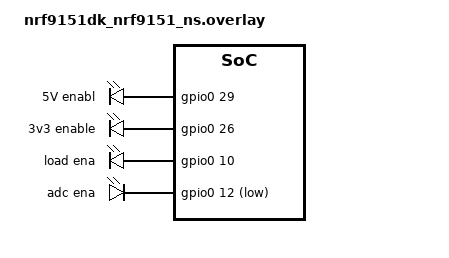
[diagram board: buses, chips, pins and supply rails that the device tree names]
// To get started, press Ctrl+Space to bring up the completion menu and view the available nodes.

// You can also use the buttons in the sidebar to perform actions on nodes.
// Actions currently available include:

// * Enabling / disabling the node
// * Adding the bus to a bus
// * Removing the node
// * Connecting ADC channels

// For more help, browse the DeviceTree documentation at https://docs.zephyrproject.org/latest/guides/dts/index.html
// You can also visit the nRF DeviceTree extension documentation at https://docs.nordicsemi.com/bundle/nrf-connect-vscode/page/guides/ncs_configure_app.html#devicetree-support-in-the-extension

&led0 {
	gpios = <&gpio0 29 0>;
	label = "5V enabl";
};

&led1 {
	gpios = <&gpio0 26 0>;
	label = "3v3 enable";
};



&uart0_default {
	group2 {
		psels = <NRF_PSEL(UART_RX, 0, 28)>, <NRF_PSEL(UART_CTS, 0, 15)>;
	};
};

&uart0_sleep {
	group1 {
		psels = <NRF_PSEL(UART_TX, 0, 27)>,
				<NRF_PSEL(UART_RX, 0, 28)>,
				<NRF_PSEL(UART_RTS, 0, 14)>,
				<NRF_PSEL(UART_CTS, 0, 15)>;
	};
};

&led2 {
	gpios = <&gpio0 10 0>;
	label = "load ena";
};

&spi3 {
	cs-gpios = <&gpio0 20 GPIO_ACTIVE_LOW>;
};

&led3 {
	gpios = <&gpio0 12 GPIO_ACTIVE_LOW>;
	label = "adc ena";
};

&spi3_default {
	group1 {
		psels = <NRF_PSEL(SPIM_SCK, 0, 13)>,
				<NRF_PSEL(SPIM_MISO, 0, 16)>,
				<NRF_PSEL(SPIM_MOSI, 0, 11)>;
		nordic,drive-mode = <NRF_DRIVE_H0H1>;
	};
};

&spi3_sleep {
	group1 {
		psels = <NRF_PSEL(SPIM_SCK, 0, 13)>,
				<NRF_PSEL(SPIM_MISO, 0, 16)>,
				<NRF_PSEL(SPIM_MOSI, 0, 11)>;
	};
};

&arduino_adc {
    io-channel-map = <0 &adc 1>,
                     <1 &adc 2>,
                     <2 &adc 4>,
                     <3 &adc 5>,
                     <4 &adc 6>,
                     <5 &adc 7>;
};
